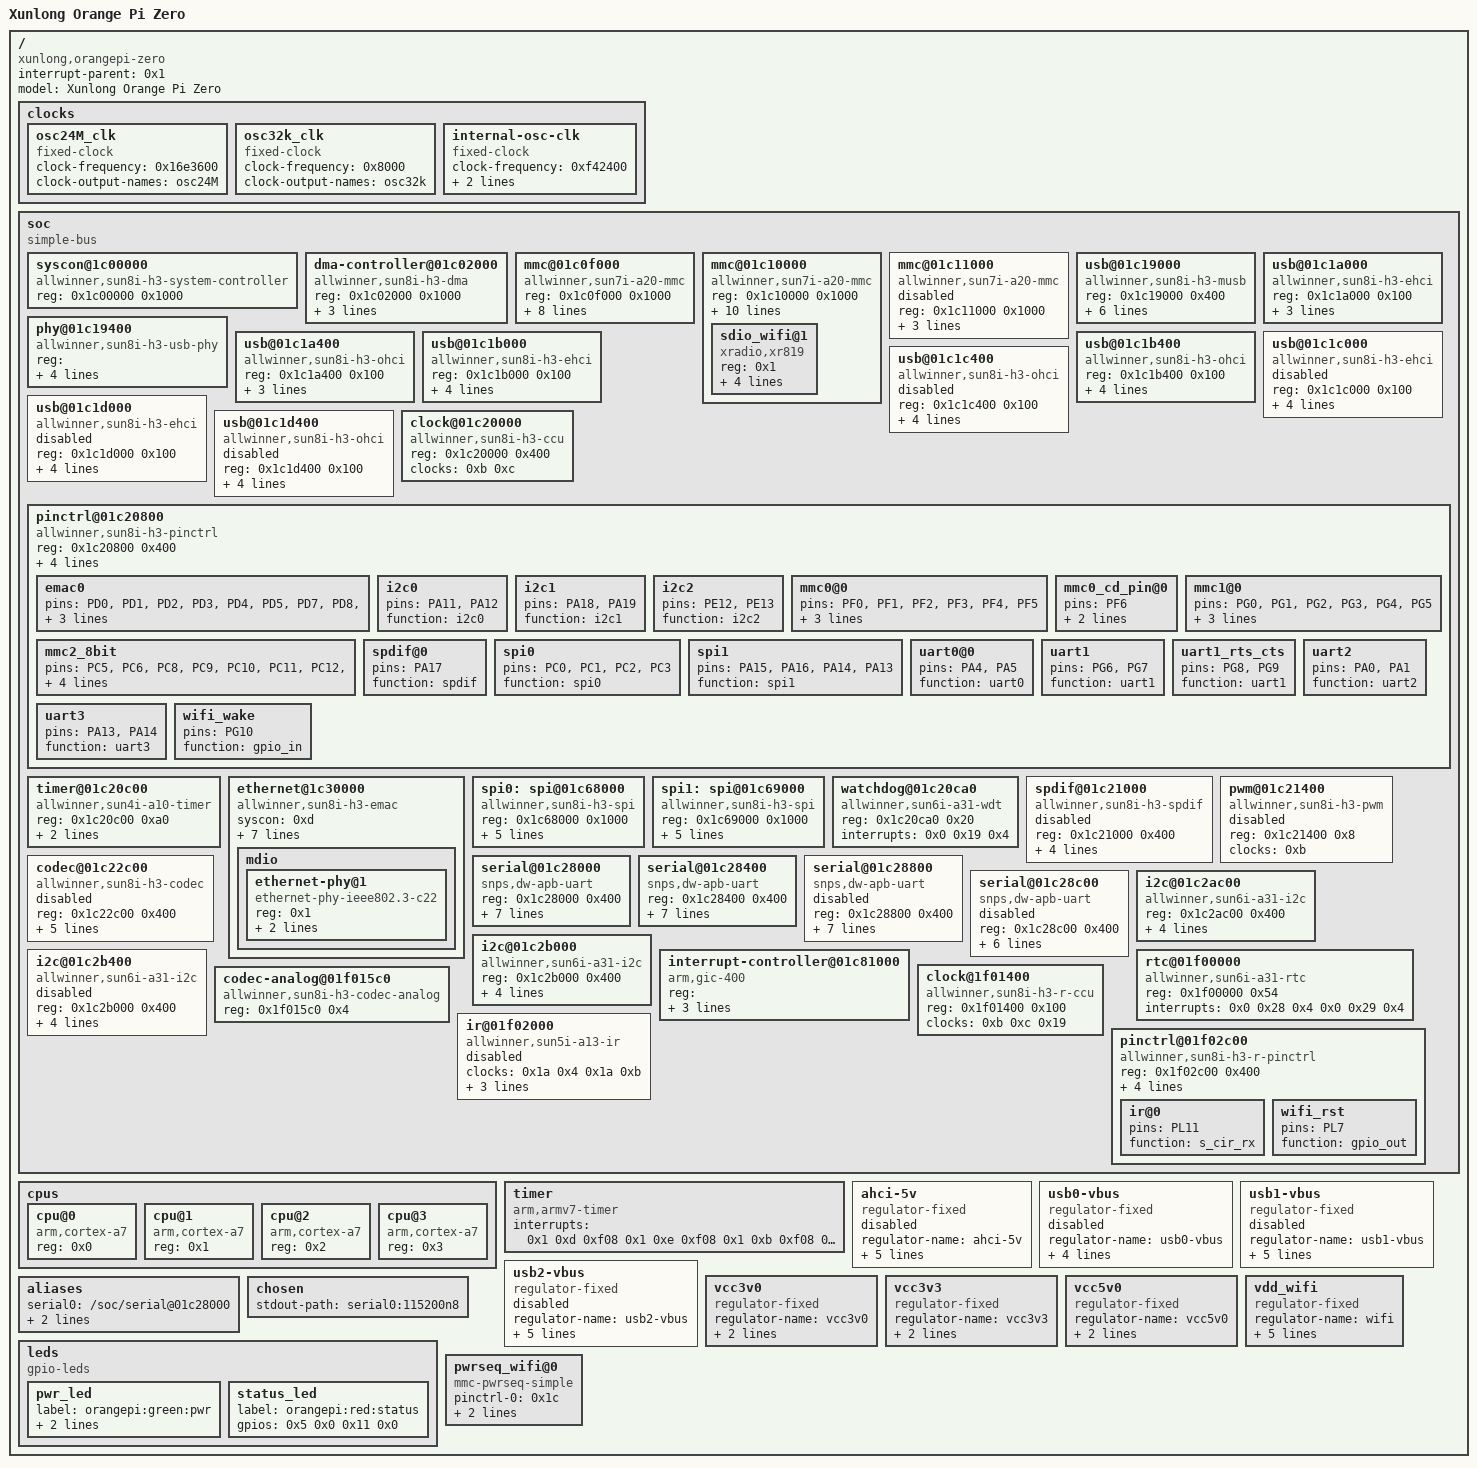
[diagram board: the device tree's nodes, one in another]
/dts-v1/;

/ {
        interrupt-parent = <0x1>;
        #address-cells = <0x1>;
        #size-cells = <0x1>;
        model = "Xunlong Orange Pi Zero";
        compatible = "xunlong,orangepi-zero", "allwinner,sun8i-h2-plus";

        clocks {
                #address-cells = <0x1>;
                #size-cells = <0x1>;
                ranges;

                osc24M_clk {
                        #clock-cells = <0x0>;
                        compatible = "fixed-clock";
                        clock-frequency = <0x16e3600>;
                        clock-output-names = "osc24M";
                        linux,phandle = <0xb>;
                        phandle = <0xb>;
                };

                osc32k_clk {
                        #clock-cells = <0x0>;
                        compatible = "fixed-clock";
                        clock-frequency = <0x8000>;
                        clock-output-names = "osc32k";
                        linux,phandle = <0xc>;
                        phandle = <0xc>;
                };

                internal-osc-clk {
                        #clock-cells = <0x0>;
                        compatible = "fixed-clock";
                        clock-frequency = <0xf42400>;
                        clock-accuracy = <0x11e1a300>;
                        clock-output-names = "iosc";
                        linux,phandle = <0x19>;
                        phandle = <0x19>;
                };
        };

        soc {
                compatible = "simple-bus";
                #address-cells = <0x1>;
                #size-cells = <0x1>;
                ranges;

                syscon@1c00000 {
                        compatible = "allwinner,sun8i-h3-system-controller", "syscon";
                        reg = <0x1c00000 0x1000>;
                        linux,phandle = <0xd>;
                        phandle = <0xd>;
                };

                dma-controller@01c02000 {
                        compatible = "allwinner,sun8i-h3-dma";
                        reg = <0x1c02000 0x1000>;
                        interrupts = <0x0 0x32 0x4>;
                        clocks = <0x2 0x15>;
                        resets = <0x2 0x6>;
                        #dma-cells = <0x1>;
                        linux,phandle = <0xf>;
                        phandle = <0xf>;
                };

                mmc@01c0f000 {
                        reg = <0x1c0f000 0x1000>;
                        resets = <0x2 0x7>;
                        reset-names = "ahb";
                        interrupts = <0x0 0x3c 0x4>;
                        status = "okay";
                        #address-cells = <0x1>;
                        #size-cells = <0x0>;
                        compatible = "allwinner,sun7i-a20-mmc";
                        clocks = <0x2 0x16 0x2 0x47 0x2 0x49 0x2 0x48>;
                        clock-names = "ahb", "mmc", "output", "sample";
                        pinctrl-names = "default";
                        pinctrl-0 = <0x3>;
                        vmmc-supply = <0x4>;
                        bus-width = <0x4>;
                        cd-gpios = <0x5 0x5 0x6 0x0>;
                        cd-inverted;
                };

                mmc@01c10000 {
                        reg = <0x1c10000 0x1000>;
                        resets = <0x2 0x8>;
                        reset-names = "ahb";
                        interrupts = <0x0 0x3d 0x4>;
                        status = "okay";
                        #address-cells = <0x1>;
                        #size-cells = <0x0>;
                        compatible = "allwinner,sun7i-a20-mmc";
                        clocks = <0x2 0x17 0x2 0x4a 0x2 0x4c 0x2 0x4b>;
                        clock-names = "ahb", "mmc", "output", "sample";
                        pinctrl-names = "default";
                        pinctrl-0 = <0x6>;
                        vmmc-supply = <0x4>;
                        vqmmc-supply = <0x7>;
                        mmc-pwrseq = <0x8>;
                        bus-width = <0x4>;
                        max-frequency = <0xf42400>;
                        non-removable;

                        sdio_wifi@1 {
                                reg = <0x1>;
                                compatible = "xradio,xr819";
                                pinctrl-names = "default";
                                pinctrl-0 = <0x9>;
                                interrupt-parent = <0x5>;
                                interrupts = <0x6 0xa 0x1>;
                                interrupt-names = "host-wake";
                                local-mac-address = [dc 44 6d c0 ff ee];
                        };
                };

                mmc@01c11000 {
                        reg = <0x1c11000 0x1000>;
                        resets = <0x2 0x9>;
                        reset-names = "ahb";
                        interrupts = <0x0 0x3e 0x4>;
                        status = "disabled";
                        #address-cells = <0x1>;
                        #size-cells = <0x0>;
                        compatible = "allwinner,sun7i-a20-mmc";
                        clocks = <0x2 0x18 0x2 0x4d 0x2 0x4f 0x2 0x4e>;
                        clock-names = "ahb", "mmc", "output", "sample";
                };

                usb@01c19000 {
                        compatible = "allwinner,sun8i-h3-musb";
                        reg = <0x1c19000 0x400>;
                        clocks = <0x2 0x20>;
                        resets = <0x2 0x11>;
                        interrupts = <0x0 0x47 0x4>;
                        interrupt-names = "mc";
                        phys = <0xa 0x0>;
                        phy-names = "usb";
                        extcon = <0xa 0x0>;
                        status = "okay";
                        dr_mode = "peripheral";
                };

                phy@01c19400 {
                        compatible = "allwinner,sun8i-h3-usb-phy";
                        reg = <0x1c19400 0x2c 0x1c1a800 0x4 0x1c1b800 0x4 0x1c1c800 0x4 0x1c1d800 0x4>;
                        reg-names = "phy_ctrl", "pmu0", "pmu1", "pmu2", "pmu3";
                        clocks = <0x2 0x58 0x2 0x59 0x2 0x5a 0x2 0x5b>;
                        clock-names = "usb0_phy", "usb1_phy", "usb2_phy", "usb3_phy";
                        resets = <0x2 0x0 0x2 0x1 0x2 0x2 0x2 0x3>;
                        reset-names = "usb0_reset", "usb1_reset", "usb2_reset", "usb3_reset";
                        status = "okay";
                        #phy-cells = <0x1>;
                        usb0_id_det-gpios = <0x5 0x6 0xc 0x0>;
                        linux,phandle = <0xa>;
                        phandle = <0xa>;
                };

                usb@01c1a000 {
                        compatible = "allwinner,sun8i-h3-ehci", "generic-ehci";
                        reg = <0x1c1a000 0x100>;
                        interrupts = <0x0 0x48 0x4>;
                        clocks = <0x2 0x21 0x2 0x25>;
                        resets = <0x2 0x12 0x2 0x16>;
                        status = "okay";
                };

                usb@01c1a400 {
                        compatible = "allwinner,sun8i-h3-ohci", "generic-ohci";
                        reg = <0x1c1a400 0x100>;
                        interrupts = <0x0 0x49 0x4>;
                        clocks = <0x2 0x21 0x2 0x25 0x2 0x5c>;
                        resets = <0x2 0x12 0x2 0x16>;
                        status = "okay";
                };

                usb@01c1b000 {
                        compatible = "allwinner,sun8i-h3-ehci", "generic-ehci";
                        reg = <0x1c1b000 0x100>;
                        interrupts = <0x0 0x4a 0x4>;
                        clocks = <0x2 0x22 0x2 0x26>;
                        resets = <0x2 0x13 0x2 0x17>;
                        phys = <0xa 0x1>;
                        phy-names = "usb";
                        status = "okay";
                };

                usb@01c1b400 {
                        compatible = "allwinner,sun8i-h3-ohci", "generic-ohci";
                        reg = <0x1c1b400 0x100>;
                        interrupts = <0x0 0x4b 0x4>;
                        clocks = <0x2 0x22 0x2 0x26 0x2 0x5d>;
                        resets = <0x2 0x13 0x2 0x17>;
                        phys = <0xa 0x1>;
                        phy-names = "usb";
                        status = "okay";
                };

                usb@01c1c000 {
                        compatible = "allwinner,sun8i-h3-ehci", "generic-ehci";
                        reg = <0x1c1c000 0x100>;
                        interrupts = <0x0 0x4c 0x4>;
                        clocks = <0x2 0x23 0x2 0x27>;
                        resets = <0x2 0x14 0x2 0x18>;
                        phys = <0xa 0x2>;
                        phy-names = "usb";
                        status = "disabled";
                };

                usb@01c1c400 {
                        compatible = "allwinner,sun8i-h3-ohci", "generic-ohci";
                        reg = <0x1c1c400 0x100>;
                        interrupts = <0x0 0x4d 0x4>;
                        clocks = <0x2 0x23 0x2 0x27 0x2 0x5e>;
                        resets = <0x2 0x14 0x2 0x18>;
                        phys = <0xa 0x2>;
                        phy-names = "usb";
                        status = "disabled";
                };

                usb@01c1d000 {
                        compatible = "allwinner,sun8i-h3-ehci", "generic-ehci";
                        reg = <0x1c1d000 0x100>;
                        interrupts = <0x0 0x4e 0x4>;
                        clocks = <0x2 0x24 0x2 0x28>;
                        resets = <0x2 0x15 0x2 0x19>;
                        phys = <0xa 0x3>;
                        phy-names = "usb";
                        status = "disabled";
                };

                usb@01c1d400 {
                        compatible = "allwinner,sun8i-h3-ohci", "generic-ohci";
                        reg = <0x1c1d400 0x100>;
                        interrupts = <0x0 0x4f 0x4>;
                        clocks = <0x2 0x24 0x2 0x28 0x2 0x5f>;
                        resets = <0x2 0x15 0x2 0x19>;
                        phys = <0xa 0x3>;
                        phy-names = "usb";
                        status = "disabled";
                };

                clock@01c20000 {
                        reg = <0x1c20000 0x400>;
                        clocks = <0xb 0xc>;
                        clock-names = "hosc", "losc";
                        #clock-cells = <0x1>;
                        #reset-cells = <0x1>;
                        compatible = "allwinner,sun8i-h3-ccu";
                        linux,phandle = <0x2>;
                        phandle = <0x2>;
                };

                pinctrl@01c20800 {
                        reg = <0x1c20800 0x400>;
                        interrupts = <0x0 0xb 0x4 0x0 0x11 0x4>;
                        clocks = <0x2 0x36 0xb 0xc>;
                        clock-names = "apb", "hosc", "losc";
                        gpio-controller;
                        #gpio-cells = <0x3>;
                        interrupt-controller;
                        #interrupt-cells = <0x3>;
                        compatible = "allwinner,sun8i-h3-pinctrl";
                        linux,phandle = <0x5>;
                        phandle = <0x5>;

                        emac0 {
                                pins = "PD0", "PD1", "PD2", "PD3", "PD4", "PD5", "PD7", "PD8", "PD9", "PD10", "PD12", "PD13", "PD15", "PD16", "PD17";
                                function = "emac";
                                drive-strength = <0x28>;
                        };

                        i2c0 {
                                pins = "PA11", "PA12";
                                function = "i2c0";
                                linux,phandle = <0x16>;
                                phandle = <0x16>;
                        };

                        i2c1 {
                                pins = "PA18", "PA19";
                                function = "i2c1";
                                linux,phandle = <0x17>;
                                phandle = <0x17>;
                        };

                        i2c2 {
                                pins = "PE12", "PE13";
                                function = "i2c2";
                                linux,phandle = <0x18>;
                                phandle = <0x18>;
                        };

                        mmc0@0 {
                                pins = "PF0", "PF1", "PF2", "PF3", "PF4", "PF5";
                                function = "mmc0";
                                drive-strength = <0x1e>;
                                bias-pull-up;
                                linux,phandle = <0x3>;
                                phandle = <0x3>;
                        };

                        mmc0_cd_pin@0 {
                                pins = "PF6";
                                function = "gpio_in";
                                bias-pull-up;
                        };

                        mmc1@0 {
                                pins = "PG0", "PG1", "PG2", "PG3", "PG4", "PG5";
                                function = "mmc1";
                                drive-strength = <0x1e>;
                                bias-pull-up;
                                linux,phandle = <0x6>;
                                phandle = <0x6>;
                        };

                        mmc2_8bit {
                                pins = "PC5", "PC6", "PC8", "PC9", "PC10", "PC11", "PC12", "PC13", "PC14", "PC15", "PC16";
                                function = "mmc2";
                                drive-strength = <0x1e>;
                                bias-pull-up;
                        };

                        spdif@0 {
                                pins = "PA17";
                                function = "spdif";
                        };

                        spi0 {
                                pins = "PC0", "PC1", "PC2", "PC3";
                                function = "spi0";
                                linux,phandle = <0x10>;
                                phandle = <0x10>;
                        };

                        spi1 {
                                pins = "PA15", "PA16", "PA14", "PA13";
                                function = "spi1";
                                linux,phandle = <0x11>;
                                phandle = <0x11>;
                        };

                        uart0@0 {
                                pins = "PA4", "PA5";
                                function = "uart0";
                                linux,phandle = <0x13>;
                                phandle = <0x13>;
                        };

                        uart1 {
                                pins = "PG6", "PG7";
                                function = "uart1";
                                linux,phandle = <0x14>;
                                phandle = <0x14>;
                        };

                        uart1_rts_cts {
                                pins = "PG8", "PG9";
                                function = "uart1";
                        };

                        uart2 {
                                pins = "PA0", "PA1";
                                function = "uart2";
                                linux,phandle = <0x15>;
                                phandle = <0x15>;
                        };

                        uart3 {
                                pins = "PA13", "PA14";
                                function = "uart3";
                        };

                        wifi_wake {
                                pins = "PG10";
                                function = "gpio_in";
                                linux,phandle = <0x9>;
                                phandle = <0x9>;
                        };
                };

                timer@01c20c00 {
                        compatible = "allwinner,sun4i-a10-timer";
                        reg = <0x1c20c00 0xa0>;
                        interrupts = <0x0 0x12 0x4 0x0 0x13 0x4>;
                        clocks = <0xb>;
                };

                ethernet@1c30000 {
                        compatible = "allwinner,sun8i-h3-emac";
                        syscon = <0xd>;
                        reg = <0x1c30000 0x104>;
                        interrupts = <0x0 0x52 0x4>;
                        interrupt-names = "macirq";
                        resets = <0x2 0xc>;
                        reset-names = "stmmaceth";
                        clocks = <0x2 0x1b>;
                        clock-names = "stmmaceth";
                        #address-cells = <0x1>;
                        #size-cells = <0x0>;
                        status = "okay";
                        phy-handle = <0xe>;
                        phy-mode = "mii";
                        allwinner,leds-active-low;

                        mdio {
                                #address-cells = <0x1>;
                                #size-cells = <0x0>;

                                ethernet-phy@1 {
                                        compatible = "ethernet-phy-ieee802.3-c22";
                                        reg = <0x1>;
                                        clocks = <0x2 0x43>;
                                        resets = <0x2 0x27>;
                                        linux,phandle = <0xe>;
                                        phandle = <0xe>;
                                };
                        };
                };

                spi0: spi@01c68000 {
                        compatible = "allwinner,sun8i-h3-spi";
                        reg = <0x1c68000 0x1000>;
                        interrupts = <0x0 0x41 0x4>;
                        clocks = <0x2 0x1e 0x2 0x52>;
                        clock-names = "ahb", "mod";
                        dmas = <0xf 0x17 0xf 0x17>;
                        dma-names = "rx", "tx";
                        pinctrl-names = "default";
                        pinctrl-0 = <0x10>;
                        resets = <0x2 0xf>;
                        status = "okay";
                        #address-cells = <0x1>;
                        #size-cells = <0x0>;
                };

                spi1: spi@01c69000 {
                        compatible = "allwinner,sun8i-h3-spi";
                        reg = <0x1c69000 0x1000>;
                        interrupts = <0x0 0x42 0x4>;
                        clocks = <0x2 0x1f 0x2 0x53>;
                        clock-names = "ahb", "mod";
                        dmas = <0xf 0x18 0xf 0x18>;
                        dma-names = "rx", "tx";
                        pinctrl-names = "default";
                        pinctrl-0 = <0x11>;
                        resets = <0x2 0x10>;
                        status = "okay";
                        #address-cells = <0x1>;
                        #size-cells = <0x0>;
                };

                watchdog@01c20ca0 {
                        compatible = "allwinner,sun6i-a31-wdt";
                        reg = <0x1c20ca0 0x20>;
                        interrupts = <0x0 0x19 0x4>;
                };

                spdif@01c21000 {
                        #sound-dai-cells = <0x0>;
                        compatible = "allwinner,sun8i-h3-spdif";
                        reg = <0x1c21000 0x400>;
                        interrupts = <0x0 0xc 0x4>;
                        clocks = <0x2 0x35 0x2 0x57>;
                        resets = <0x2 0x29>;
                        clock-names = "apb", "spdif";
                        dmas = <0xf 0x2>;
                        dma-names = "tx";
                        status = "disabled";
                };

                pwm@01c21400 {
                        compatible = "allwinner,sun8i-h3-pwm";
                        reg = <0x1c21400 0x8>;
                        clocks = <0xb>;
                        #pwm-cells = <0x3>;
                        status = "disabled";
                };

                codec@01c22c00 {
                        #sound-dai-cells = <0x0>;
                        compatible = "allwinner,sun8i-h3-codec";
                        reg = <0x1c22c00 0x400>;
                        interrupts = <0x0 0x1d 0x4>;
                        clocks = <0x2 0x34 0x2 0x6d>;
                        clock-names = "apb", "codec";
                        resets = <0x2 0x28>;
                        dmas = <0xf 0xf 0xf 0xf>;
                        dma-names = "rx", "tx";
                        allwinner,codec-analog-controls = <0x12>;
                        status = "disabled";
                };

                serial@01c28000 {
                        compatible = "snps,dw-apb-uart";
                        reg = <0x1c28000 0x400>;
                        interrupts = <0x0 0x0 0x4>;
                        reg-shift = <0x2>;
                        reg-io-width = <0x4>;
                        clocks = <0x2 0x3e>;
                        resets = <0x2 0x31>;
                        dmas = <0xf 0x6 0xf 0x6>;
                        dma-names = "rx", "tx";
                        status = "okay";
                        pinctrl-names = "default";
                        pinctrl-0 = <0x13>;
                };

                serial@01c28400 {
                        compatible = "snps,dw-apb-uart";
                        reg = <0x1c28400 0x400>;
                        interrupts = <0x0 0x1 0x4>;
                        reg-shift = <0x2>;
                        reg-io-width = <0x4>;
                        clocks = <0x2 0x3f>;
                        resets = <0x2 0x32>;
                        dmas = <0xf 0x7 0xf 0x7>;
                        dma-names = "rx", "tx";
                        status = "okay";
                        pinctrl-names = "default";
                        pinctrl-0 = <0x14>;
                };

                serial@01c28800 {
                        compatible = "snps,dw-apb-uart";
                        reg = <0x1c28800 0x400>;
                        interrupts = <0x0 0x2 0x4>;
                        reg-shift = <0x2>;
                        reg-io-width = <0x4>;
                        clocks = <0x2 0x40>;
                        resets = <0x2 0x33>;
                        dmas = <0xf 0x8 0xf 0x8>;
                        dma-names = "rx", "tx";
                        status = "disabled";
                        pinctrl-names = "default";
                        pinctrl-0 = <0x15>;
                };

                serial@01c28c00 {
                        compatible = "snps,dw-apb-uart";
                        reg = <0x1c28c00 0x400>;
                        interrupts = <0x0 0x3 0x4>;
                        reg-shift = <0x2>;
                        reg-io-width = <0x4>;
                        clocks = <0x2 0x41>;
                        resets = <0x2 0x34>;
                        dmas = <0xf 0x9 0xf 0x9>;
                        dma-names = "rx", "tx";
                        status = "disabled";
                };

                i2c@01c2ac00 {
                        compatible = "allwinner,sun6i-a31-i2c";
                        reg = <0x1c2ac00 0x400>;
                        interrupts = <0x0 0x6 0x4>;
                        clocks = <0x2 0x3b>;
                        resets = <0x2 0x2e>;
                        pinctrl-names = "default";
                        pinctrl-0 = <0x16>;
                        status = "okay";
                        #address-cells = <0x1>;
                        #size-cells = <0x0>;
                };

                i2c@01c2b000 {
                        compatible = "allwinner,sun6i-a31-i2c";
                        reg = <0x1c2b000 0x400>;
                        interrupts = <0x0 0x7 0x4>;
                        clocks = <0x2 0x3c>;
                        resets = <0x2 0x2f>;
                        pinctrl-names = "default";
                        pinctrl-0 = <0x17>;
                        status = "okay";
                        #address-cells = <0x1>;
                        #size-cells = <0x0>;
                };

                i2c@01c2b400 {
                        compatible = "allwinner,sun6i-a31-i2c";
                        reg = <0x1c2b000 0x400>;
                        interrupts = <0x0 0x8 0x4>;
                        clocks = <0x2 0x3d>;
                        resets = <0x2 0x30>;
                        pinctrl-names = "default";
                        pinctrl-0 = <0x18>;
                        status = "disabled";
                        #address-cells = <0x1>;
                        #size-cells = <0x0>;
                };

                interrupt-controller@01c81000 {
                        compatible = "arm,gic-400";
                        reg = <0x1c81000 0x1000 0x1c82000 0x2000 0x1c84000 0x2000 0x1c86000 0x2000>;
                        interrupt-controller;
                        #interrupt-cells = <0x3>;
                        interrupts = <0x1 0x9 0xf04>;
                        linux,phandle = <0x1>;
                        phandle = <0x1>;
                };

                rtc@01f00000 {
                        compatible = "allwinner,sun6i-a31-rtc";
                        reg = <0x1f00000 0x54>;
                        interrupts = <0x0 0x28 0x4 0x0 0x29 0x4>;
                };

                clock@1f01400 {
                        compatible = "allwinner,sun8i-h3-r-ccu";
                        reg = <0x1f01400 0x100>;
                        clocks = <0xb 0xc 0x19>;
                        clock-names = "hosc", "losc", "iosc";
                        #clock-cells = <0x1>;
                        #reset-cells = <0x1>;
                        linux,phandle = <0x1a>;
                        phandle = <0x1a>;
                };

                codec-analog@01f015c0 {
                        compatible = "allwinner,sun8i-h3-codec-analog";
                        reg = <0x1f015c0 0x4>;
                        linux,phandle = <0x12>;
                        phandle = <0x12>;
                };

                ir@01f02000 {
                        compatible = "allwinner,sun5i-a13-ir";
                        clocks = <0x1a 0x4 0x1a 0xb>;
                        clock-names = "apb", "ir";
                        resets = <0x1a 0x0>;
                        interrupts = <0x0 0x25 0x4>;
                        reg = <0x1f02000 0x40>;
                        status = "disabled";
                };

                pinctrl@01f02c00 {
                        compatible = "allwinner,sun8i-h3-r-pinctrl";
                        reg = <0x1f02c00 0x400>;
                        interrupts = <0x0 0x2d 0x4>;
                        clocks = <0x1a 0x3 0xb 0xc>;
                        clock-names = "apb", "hosc", "losc";
                        gpio-controller;
                        #gpio-cells = <0x3>;
                        interrupt-controller;
                        #interrupt-cells = <0x3>;
                        linux,phandle = <0x1b>;
                        phandle = <0x1b>;

                        ir@0 {
                                pins = "PL11";
                                function = "s_cir_rx";
                        };

                        wifi_rst {
                                pins = "PL7";
                                function = "gpio_out";
                                linux,phandle = <0x1c>;
                                phandle = <0x1c>;
                        };
                };
        };

        cpus {
                #address-cells = <0x1>;
                #size-cells = <0x0>;

                cpu@0 {
                        compatible = "arm,cortex-a7";
                        device_type = "cpu";
                        reg = <0x0>;
                };

                cpu@1 {
                        compatible = "arm,cortex-a7";
                        device_type = "cpu";
                        reg = <0x1>;
                };

                cpu@2 {
                        compatible = "arm,cortex-a7";
                        device_type = "cpu";
                        reg = <0x2>;
                };

                cpu@3 {
                        compatible = "arm,cortex-a7";
                        device_type = "cpu";
                        reg = <0x3>;
                };
        };

        timer {
                compatible = "arm,armv7-timer";
                interrupts = <0x1 0xd 0xf08 0x1 0xe 0xf08 0x1 0xb 0xf08 0x1 0xa 0xf08>;
        };

        ahci-5v {
                compatible = "regulator-fixed";
                regulator-name = "ahci-5v";
                regulator-min-microvolt = <0x4c4b40>;
                regulator-max-microvolt = <0x4c4b40>;
                regulator-boot-on;
                enable-active-high;
                gpio = <0x5 0x1 0x8 0x0>;
                status = "disabled";
        };

        usb0-vbus {
                compatible = "regulator-fixed";
                regulator-name = "usb0-vbus";
                regulator-min-microvolt = <0x4c4b40>;
                regulator-max-microvolt = <0x4c4b40>;
                enable-active-high;
                gpio = <0x5 0x1 0x9 0x0>;
                status = "disabled";
        };

        usb1-vbus {
                compatible = "regulator-fixed";
                regulator-name = "usb1-vbus";
                regulator-min-microvolt = <0x4c4b40>;
                regulator-max-microvolt = <0x4c4b40>;
                regulator-boot-on;
                enable-active-high;
                gpio = <0x5 0x7 0x6 0x0>;
                status = "disabled";
        };

        usb2-vbus {
                compatible = "regulator-fixed";
                regulator-name = "usb2-vbus";
                regulator-min-microvolt = <0x4c4b40>;
                regulator-max-microvolt = <0x4c4b40>;
                regulator-boot-on;
                enable-active-high;
                gpio = <0x5 0x7 0x3 0x0>;
                status = "disabled";
        };

        vcc3v0 {
                compatible = "regulator-fixed";
                regulator-name = "vcc3v0";
                regulator-min-microvolt = <0x2dc6c0>;
                regulator-max-microvolt = <0x2dc6c0>;
        };

        vcc3v3 {
                compatible = "regulator-fixed";
                regulator-name = "vcc3v3";
                regulator-min-microvolt = <0x325aa0>;
                regulator-max-microvolt = <0x325aa0>;
                linux,phandle = <0x4>;
                phandle = <0x4>;
        };

        vcc5v0 {
                compatible = "regulator-fixed";
                regulator-name = "vcc5v0";
                regulator-min-microvolt = <0x4c4b40>;
                regulator-max-microvolt = <0x4c4b40>;
        };

        aliases {
                serial0 = "/soc/serial@01c28000";
                ethernet0 = "/soc/ethernet@1c30000";
                ethernet1 = "/soc/mmc@01c10000/sdio_wifi@1";
        };

        chosen {
                stdout-path = "serial0:115200n8";
        };

        leds {
                compatible = "gpio-leds";

                pwr_led {
                        label = "orangepi:green:pwr";
                        gpios = <0x1b 0x0 0xa 0x0>;
                        default-state = "on";
                };

                status_led {
                        label = "orangepi:red:status";
                        gpios = <0x5 0x0 0x11 0x0>;
                };
        };

        vdd_wifi {
                compatible = "regulator-fixed";
                regulator-name = "wifi";
                regulator-min-microvolt = <0x1b7740>;
                regulator-max-microvolt = <0x1b7740>;
                gpio = <0x5 0x0 0x14 0x0>;
                startup-delay-us = <0x11170>;
                enable-active-high;
                linux,phandle = <0x7>;
                phandle = <0x7>;
        };

        pwrseq_wifi@0 {
                compatible = "mmc-pwrseq-simple";
                pinctrl-names = "default";
                pinctrl-0 = <0x1c>;
                reset-gpios = <0x1b 0x0 0x7 0x1>;
                post-power-on-delay-ms = <0x32>;
                linux,phandle = <0x8>;
                phandle = <0x8>;
        };
};

